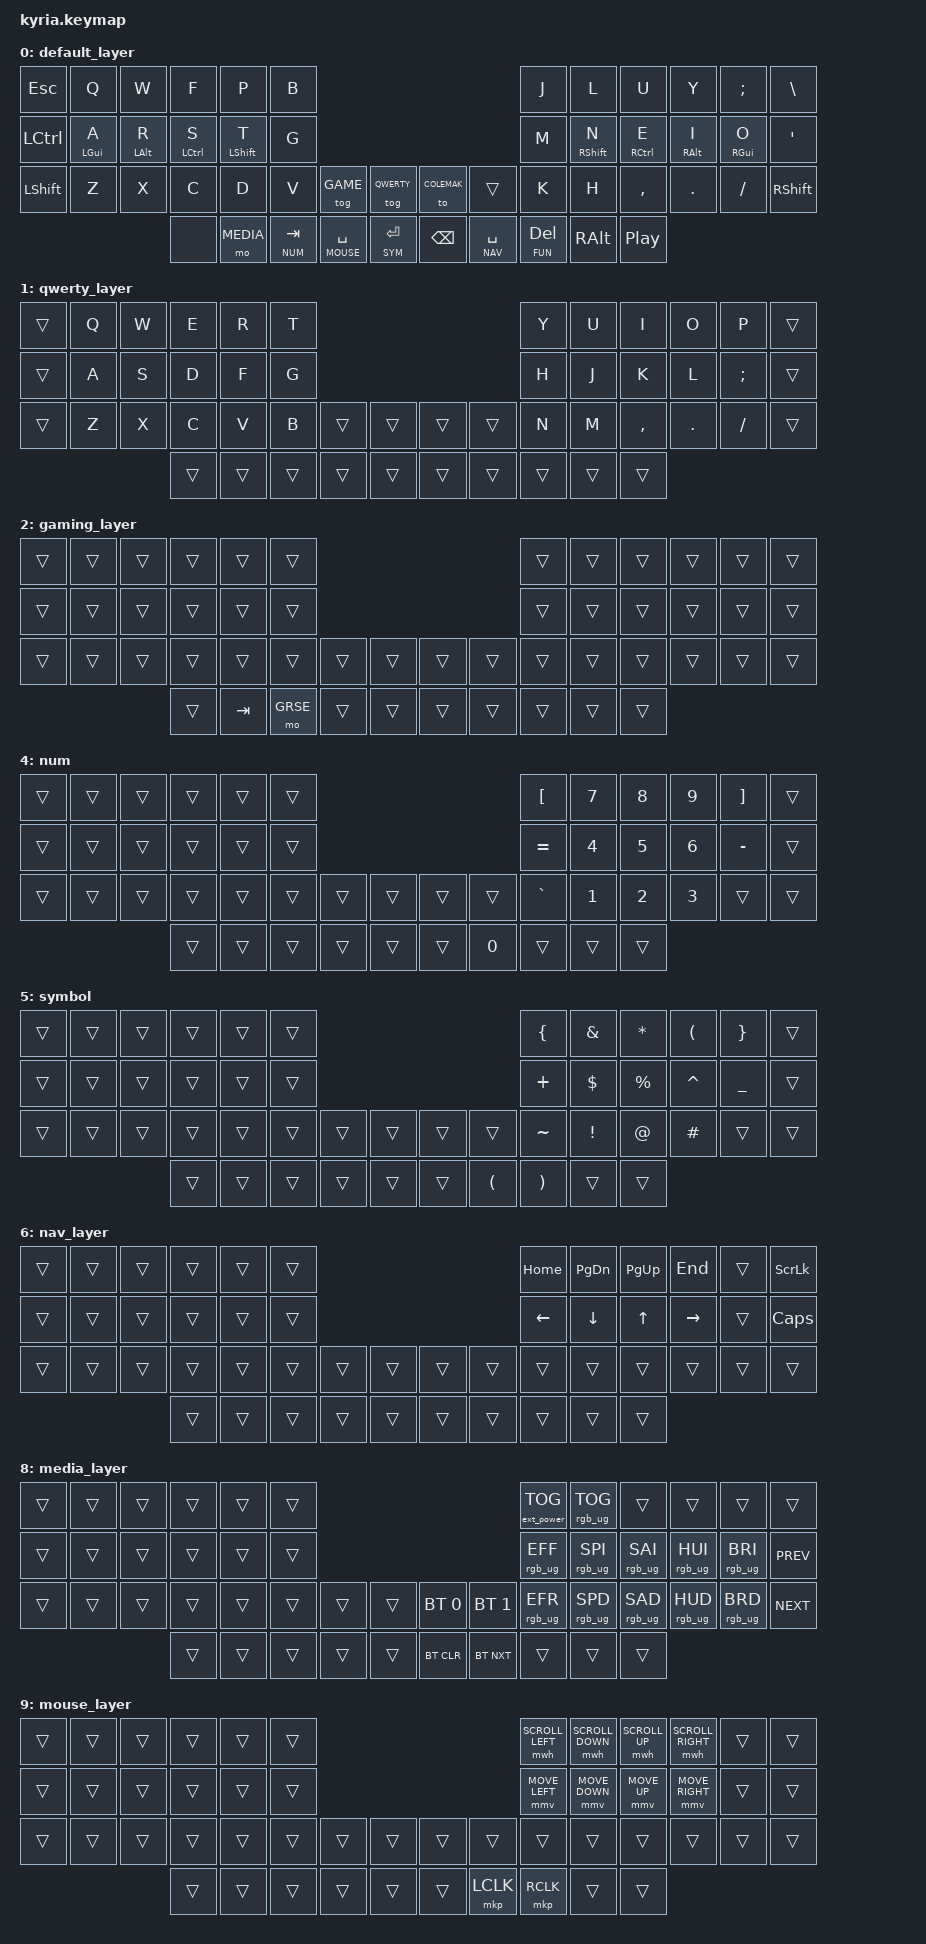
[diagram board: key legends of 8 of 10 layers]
/*
 * Copyright (c) 2020 The ZMK Contributors
 *
 * SPDX-License-Identifier: MIT
 */

#include <behaviors.dtsi>
#include <dt-bindings/zmk/keys.h>
#include <dt-bindings/zmk/bt.h>
#include <dt-bindings/zmk/rgb.h>
#include <dt-bindings/zmk/ext_power.h>
#include <dt-bindings/zmk/mouse.h>

/*
 * Temporarily here because nice nano v2 spi is not defined on ZMk Yet
 * Source: https://github.com/zmkfirmware/zmk/blob/main/app/boards/shields/reviung41/boards/nice_nano.overlay
 * GitHub Issue: https://github.com/zmkfirmware/zmk/issues/885
 */

&spi1 {
   compatible = "nordic,nrf-spim";
   status = "okay";
   mosi-pin = <6>;
   // Unused pins, needed for SPI definition, but not used by the ws2812 driver itself.
   sck-pin = <5>;
   miso-pin = <7>;

   led_strip: ws2812@0 {
      compatible = "worldsemi,ws2812-spi";
      label = "WS2812";

      /* SPI */
      reg = <0>; /* ignored, but necessary for SPI bindings */
      spi-max-frequency = <4000000>;

      /* WS2812 */
      chain-length = <11>; /* arbitrary; change at will */
      spi-one-frame = <0x70>;
      spi-zero-frame = <0x40>;
   };
};

/ {
   chosen {
      zmk,underglow = &led_strip;
   };
};



#define COLEMAK 0
#define QWERTY  1
#define GAME    2
#define GRSE    3 // A special raise layer for main-half gaming.
#define NUM     4
#define SYM     5
#define NAV     6
#define FUN     7
#define MEDIA   8
#define MOUSE   9


/ {
    behaviors {
        hm: homerow_mods {
            compatible = "zmk,behavior-hold-tap";
            label = "HOMEROW_MODS";
            #binding-cells = <2>;
            tapping-term-ms = <175>;
            quick-tap-ms = <0>;
            flavor = "tap-preferred";
            bindings = <&kp>, <&kp>;
        };
    };

	keymap {
		compatible = "zmk,keymap";

		default_layer {
// ---------------------------------------------------------------------------------------------------------------------------------
// |  ESC  |  Q   |  W   |  F   |  P   |  B   |                                       |   J   |   L   |   U   |   Y   |   :   |   \   |
// |  CTRL |  A   |  R   |  S   |  T   |  G   |                                       |   M   |   N   |   E   |   I   |   O   |   '   |
// | SHIFT |  Z   |  X   |  C   |  D   |  V   | GAMG  | QWTY |         | DFLT | _____ |   K   |   H   |   ,   |   .   |   /   | SHIFT |
//                       |      | MEDIA| Tab  | SPACE | RET  |         | BSPC | SPACE |  DEL  | R-ALT |  PP   |
//                                       /Num   /MOUSE  /SYM                    /NAV     /FUN
			bindings = <
	&kp ESC   &kp Q      &kp W      &kp F       &kp P       &kp B                                                         &kp J       &kp L       &kp U       &kp Y      &kp SEMI   &kp BSLH
	&kp LCTRL &hm LGUI A &hm LALT R &hm LCTRL S &hm LSHFT T &kp G                                                         &kp M       &hm RSHFT N &hm RCTRL E &hm RALT I &hm RGUI O &kp SQT
	&kp LSHFT &kp Z      &kp X      &kp C       &kp D       &kp V       &tog GAME       &tog QWERTY   &to COLEMAK &trans        &kp K       &kp H       &kp COMMA   &kp DOT    &kp FSLH   &kp RSHFT
	                                &none       &mo MEDIA   &lt NUM TAB &lt MOUSE SPACE &lt SYM RET   &kp BSPC    &lt NAV SPACE &lt FUN DEL &kp RALT    &kp C_PP
			>;

			sensor-bindings = <&inc_dec_kp C_VOL_DN C_VOL_UP &inc_dec_kp C_VOL_DN C_VOL_UP>;
		};

		qwerty_layer {
// ---------------------------------------------------------------------------------------------------------------------------------
// | ____ |   Q  |  W   |  E   |  R   |  T   |                                             |  Y   |  U   |  I   |  O   |  P   | ____ |
// | ____ |   A  |  S   |  D   |  F   |  G   |                                             |  H   |  J   |  K   |  L   |  ;   | ____ |
// | ____ |   Z  |  X   |  C   |  V   |  B   | ____ | ____ |                 | ____ | ____ |  N   |  M   |  ,   |  .   |  /   | ____ |
//                      | ____ | ____ | ____ | ____ | ____ |                 | ____ | ____ | ____ | ____ | ____ |
			bindings = <
		
	&trans  &kp Q &kp W &kp E  &kp R  &kp T                                    &kp Y  &kp U  &kp I     &kp O   &kp P    &trans
	&trans  &kp A &kp S &kp D  &kp F  &kp G                                    &kp H  &kp J  &kp K     &kp L   &kp SEMI &trans
	&trans  &kp Z &kp X &kp C  &kp V  &kp B  &trans &trans       &trans &trans &kp N  &kp M  &kp COMMA &kp DOT &kp FSLH &trans
	                    &trans &trans &trans &trans &trans       &trans &trans &trans &trans &trans
			>;

			sensor-bindings = <&inc_dec_kp C_VOL_DN C_VOL_UP &inc_dec_kp C_VOL_DN C_VOL_UP>;
		};

		gaming_layer {
// --------------------------------------------------------------------------------------------------------------------------------
// | ____ | ____ | ____ | ____ | ____ | ____ |                                             | ____ | ____ | ____ | ____ | ____ | ____ |
// | ____ | ____ | ____ | ____ | ____ | ____ |                                             | ____ | ____ | ____ | ____ | ____ | ____ |
// | ____ | ____ | ____ | ____ | ____ | ____ | ____ | ____ |                 | ____ | ____ | ____ | ____ | ____ | ____ | ____ | ____ |
//                      | ____ | TAB  | GRSE | ____ | ____ |                 | ____ | ____ | ____ | ____ | ____ |
			bindings = <

	&trans &trans &trans &trans &trans  &trans                                     &trans &trans &trans &trans &trans &trans
	&trans &trans &trans &trans &trans  &trans                                     &trans &trans &trans &trans &trans &trans
	&trans &trans &trans &trans &trans  &trans   &trans &trans       &trans &trans &trans &trans &trans &trans &trans &trans
	                     &trans &kp TAB &mo GRSE &trans &trans       &trans &trans &trans &trans &trans
			>;
		};
		
		gaming_raise_layer {
// --------------------------------------------------------------------------------------------------------------------------------
// | F1   |  1   |  2   |  3   |  4   |  5   |                                             | ____ | ____ | ____ | ____ | ____ | ____ |
// | ____ | ____ | ____ | ____ | ____ | ____ |                                             | ____ | ____ | ____ | ____ | ____ | ____ |
// | ____ | ____ | ____ | ____ | ____ | ____ | ____ | ____ |                 | ____ | ____ | ____ | ____ | ____ | ____ | ____ | ____ |
//                      | ____ | ____ | ____ | ____ | ____ |                 | ____ | ____ | ____ | ____ | ____ |
			bindings = <

	&kp F1 &kp N1 &kp N2 &kp N3 &kp N4 &kp N5                                   &trans &trans &trans &trans &trans &trans
	&trans &trans &trans &trans &trans &trans                                   &trans &trans &trans &trans &trans &trans
	&trans &trans &trans &trans &trans &trans                                   &trans &trans &trans &trans &trans &trans
	                     &trans &trans &trans &trans &trans       &trans &trans &trans &trans &trans
			>;
		};
		

		num {
// ---------------------------------------------------------------------------------------------------------------------------------
// | ____ | ____ | ____ | ____ | ____ | ____ |                                             | [ {  | 7 &  | 8 *  | 9 (  |  ] } | ____ |
// | ____ | ____ | ____ | ____ | ____ | ____ |                                             | = +  | 4 $  | 5 %  | 6 ^  |  - _ | ____ |
// | ____ | ____ | ____ | ____ | ____ | ____ | ____ | ____ |                 | ____ | ____ | ` ~  | 1 !  | 2 @  | 3 #  | ____ | ____ |
//                      | ____ | ____ | ____ | ____ | ____ |                 | ____ |  0 ( | ____ | ____ | ____ |
			bindings = <
	&trans &trans &trans &trans &trans &trans                                   &kp LBKT  &kp N7 &kp N8 &kp N9 &kp RBKT  &trans
	&trans &trans &trans &trans &trans &trans                                   &kp EQUAL &kp N4 &kp N5 &kp N6 &kp MINUS &trans
	&trans &trans &trans &trans &trans &trans &trans &trans       &trans &trans &kp GRAVE &kp N1 &kp N2 &kp N3 &trans    &trans
	                     &trans &trans &trans &trans &trans       &trans &kp N0 &trans    &trans &trans
			>;
		};
		
        symbol {
// ---------------------------------------------------------------------------------------------------------------------------------
// | ____ | ____ | ____ | ____ | ____ | ____ |                                             | {    | &    | *    | (    |  }   | ____ |
// | ____ | ____ | ____ | ____ | ____ | ____ |                                             | +    | $    | %    | ^    |  _   | ____ |
// | ____ | ____ | ____ | ____ | ____ | ____ | ____ | ____ |                 | ____ | ____ | ~    | !    | @    | #    | ____ | ____ |
//                      | ____ | ____ | ____ | ____ | ____ |                 | ____ |  (   | )    | ____ | ____ |
			bindings = <
	&trans &trans &trans &trans &trans &trans                                     &kp LBRC  &kp AMPS &kp STAR  &kp LPAR  &kp RBRC  &trans
	&trans &trans &trans &trans &trans &trans                                     &kp PLUS  &kp DLLR &kp PRCNT &kp CARET &kp UNDER &trans
	&trans &trans &trans &trans &trans &trans &trans &trans       &trans &trans   &kp TILDE &kp EXCL &kp AT    &kp HASH  &trans    &trans
	                     &trans &trans &trans &trans &trans       &trans &kp LPAR &kp RPAR  &trans   &trans
			>;
		};
	
		nav_layer {
// ---------------------------------------------------------------------------------------------------------------------------------
// | ____ | ____ | ____ | ____ | ____ | ____ |                                             | Home | PgDn | PgUp | End  | ____ | Slck |
// | ____ | ____ | ____ | ____ | ____ | ____ |                                             | Left | Down |  Up  | Right| ____ | Cclk |
// | ____ | ____ | ____ | ____ | ____ | ____ | ____ | ____ |                 | ____ | ____ | ____ | ____ | ____ | ____ | ____ | ____ |
//                      | ____ | ____ | ____ | ____ | ____ |                 | ____ | ____ | ____ | ____ | ____ |
			bindings = <
	&trans &trans &trans &trans &trans &trans                                    &kp HOME  &kp PG_DN &kp PG_UP &kp END   &trans &kp SLCK
	&trans &trans &trans &trans &trans &trans                                    &kp LEFT  &kp DOWN  &kp UP    &kp RIGHT &trans &kp CLCK
	&trans &trans &trans &trans &trans &trans &trans &trans       &trans &trans  &trans    &trans    &trans    &trans    &trans &trans
	                     &trans &trans &trans &trans &trans       &trans &trans  &trans    &trans    &trans
			>;
		};
		
		fun_layer {
// ---------------------------------------------------------------------------------------------------------------------------------
// | ____ | F12  |  F7  |  F8  |  F9  | ____ |                                             | ____ | ____ | ____ | ____ | ____ | ____ |
// | ____ | F11  |  F4  |  F5  |  F6  | ____ |                                             | ____ | ____ | ____ | ____ | ____ | ____ |
// | ____ | F10  |  F1  |  F2  |  F3  | ____ | ____ | ____ |                 | ____ | ____ | ____ | ____ | ____ | ____ | ____ | ____ |
//                      | ____ | ____ | ____ | ____ | ____ |                 | ____ | ____ | ____ | ____ | ____ |
			bindings = <
	&trans &kp F12 &kp F7 &kp F8 &kp F9 &trans                                              &trans &trans &trans &trans &trans &trans
	&trans &kp F11 &kp F4 &kp F5 &kp F6 &trans                                              &trans &trans &trans &trans &trans &trans
	&trans &kp F10 &kp F1 &kp F2 &kp F3 &trans &trans &trans                  &trans &trans &trans &trans &trans
	                      &trans &trans &trans &trans &trans                  &trans &trans &trans &trans &trans
			>;
		};
	
		media_layer {
// ---------------------------------------------------------------------------------------------------------------------------------
// | ____ | ____ | ____ | ____ | ____ | ____ |                                             | VCC  | RTOG | ____ | ____ | ____ | ____   |
// | ____ | ____ | ____ | ____ | ____ | ____ |                                             | EFF  | SPI  | SAI  | HUI  | VAI  | C_PREV |
// | ____ | ____ | ____ | ____ | ____ | ____ | ____ | ____ |                 | BLS0 | BLS1 | EFR  | SPD  | SAD  | HUD  | VAD  | C_NEXT |
//                      | ____ | ____ | ____ | ____ | ____ |                 | BCLR | BNXT | ____ | ____ | ____ |
			bindings = <
	&trans &trans &trans &trans &trans &trans                                               &ext_power EP_TOG &rgb_ug RGB_TOG &trans          &trans          &trans          &trans
	&trans &trans &trans &trans &trans &trans                                               &rgb_ug RGB_EFF   &rgb_ug RGB_SPI &rgb_ug RGB_SAI &rgb_ug RGB_HUI &rgb_ug RGB_BRI &kp C_PREV
    &trans &trans &trans &trans &trans &trans &trans &trans       &bt BT_SEL 0 &bt BT_SEL 1 &rgb_ug RGB_EFR   &rgb_ug RGB_SPD &rgb_ug RGB_SAD &rgb_ug RGB_HUD &rgb_ug RGB_BRD &kp C_NEXT
                         &trans &trans &trans &trans &trans       &bt BT_CLR   &bt BT_NXT   &trans            &trans          &trans
			>;
		};
	 
		mouse_layer {
// ---------------------------------------------------------------------------------------------------------------------------------
// | ____ | ____ | ____ | ____ | ____ | ____ |                                             | SLFT | SDWN | SUP  | SRGT | ____ | ____ |
// | ____ | ____ | ____ | ____ | ____ | ____ |                                             | Left | Down |  Up  | Right| ____ | ____ |
// | ____ | ____ | ____ | ____ | ____ | ____ | ____ | ____ |                 | ____ | ____ | ____ | ____ | ____ | ____ | ____ | ____ |
//                      | ____ | ____ | ____ | ____ | ____ |                 | ____ | LCLK | RCLK | ____ | ____ |
			bindings = <
	&trans &trans &trans &trans &trans &trans                                      &mwh SCROLL_LEFT &mwh SCROLL_DOWN &mwh SCROLL_UP &mwh SCROLL_RIGHT &trans &trans
	&trans &trans &trans &trans &trans &trans                                      &mmv MOVE_LEFT   &mmv MOVE_DOWN   &mmv MOVE_UP   &mmv MOVE_RIGHT   &trans &trans
	&trans &trans &trans &trans &trans &trans &trans &trans       &trans &trans    &trans           &trans           &trans 	    &trans            &trans &trans
	                     &trans &trans &trans &trans &trans       &trans &mkp LCLK &mkp RCLK        &trans    	     &trans
			>;
		};
	};	
};
